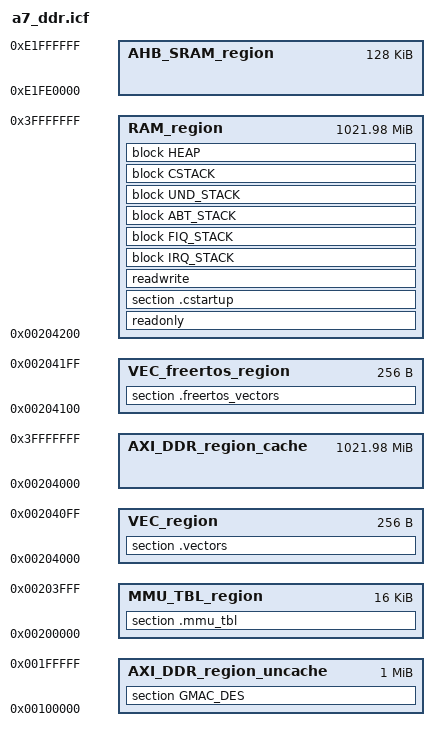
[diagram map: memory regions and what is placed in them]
/*###ICF### Section handled by ICF editor, don't touch! ****/
/*-Editor annotation file-*/
/* IcfEditorFile="$TOOLKIT_DIR$\config\ide\IcfEditor\a_v1_0.xml" */
/*-Memory Regions-*/
define symbol __ICFEDIT_region_ROM_start__ = 0x00000;
define symbol __ICFEDIT_region_ROM_end__   = 0x1ffff;

//define symbol __ICFEDIT_region_RAM_start__ = 0x20000;
define symbol __ICFEDIT_region_RAM_start__ = 0x24000;
define symbol __ICFEDIT_region_RAM_end__   = 0x5FFFF;

/* The AHB sram is uncacheable in default in the mmu_table.s */
define symbol __AHB_SRAM_START = 0xE1FE0000;
define symbol __AHB_SRAM_END = 0xE1FFFFFF;

define symbol __AXI_DDR_UNCACHE_START = 0x00100000;
define symbol __AXI_DDR_UNCACHE_END = 0x001FFFFF;

//define symbol __AXI_DDR_CACHE_START = 0x00200000;
define symbol __AXI_DDR_CACHE_START = 0x00204000;
define symbol __AXI_DDR_CACHE_END = 0x3FFFFFFF;
/*-Sizes-*/
define symbol __ICFEDIT_size_vectors__  = 0x100;
define symbol __ICFEDIT_size_freertos_vectors__  = 0x100;
define symbol __ICFEDIT_size_cstack__   = 0x4000;
define symbol __ICFEDIT_size_irqstack__ = 0x8000;
define symbol __ICFEDIT_size_fiqstack__ = 0x100;
define symbol __ICFEDIT_size_abtstack__ = 0x100;
define symbol __ICFEDIT_size_undstack__ = 0x100;

define symbol __ICFEDIT_size_heap__     = 0x600000;
/*-Exports-*/
export symbol __ICFEDIT_region_RAM_start__;
export symbol __ICFEDIT_region_RAM_end__;
export symbol __ICFEDIT_size_vectors__;
export symbol __ICFEDIT_size_cstack__;
export symbol __ICFEDIT_size_irqstack__;
export symbol __ICFEDIT_size_fiqstack__;

export symbol __ICFEDIT_size_heap__;
/**** End of ICF editor section. ###ICF###*/

define memory mem with size = 4G;
define region VEC_region = mem:[from __AXI_DDR_CACHE_START size __ICFEDIT_size_vectors__];
define region VEC_freertos_region = mem:[from __AXI_DDR_CACHE_START +__ICFEDIT_size_vectors__ size __ICFEDIT_size_freertos_vectors__];
define region RAM_region = mem:[from __AXI_DDR_CACHE_START+__ICFEDIT_size_vectors__+__ICFEDIT_size_freertos_vectors__ to __AXI_DDR_CACHE_END];
define region AHB_SRAM_region = mem:[from __AHB_SRAM_START to __AHB_SRAM_END];
define region AXI_DDR_region_uncache = mem:[from __AXI_DDR_UNCACHE_START to __AXI_DDR_UNCACHE_END];
define region AXI_DDR_region_cache = mem:[from __AXI_DDR_CACHE_START to __AXI_DDR_CACHE_END];

define block CSTACK    with alignment = 8, size = __ICFEDIT_size_cstack__   { };
define block IRQ_STACK with alignment = 8, size = __ICFEDIT_size_irqstack__ { };
define block FIQ_STACK with alignment = 8, size = __ICFEDIT_size_fiqstack__ { };
define block ABT_STACK with alignment = 8, size = __ICFEDIT_size_abtstack__ { };
define block UND_STACK with alignment = 8, size = __ICFEDIT_size_undstack__ { };
define block HEAP      with alignment = 32, size = __ICFEDIT_size_heap__     { };

initialize by copy with packing=none { readwrite };
do not initialize  { readonly section .noinit };

//define region MMU_TBL_region = mem: [from 0x20000 to 0x23FFF];
define region MMU_TBL_region = mem: [from 0x200000 to 0x203fff];
place in MMU_TBL_region { section .mmu_tbl };
place in VEC_freertos_region { section .freertos_vectors };
place in VEC_region { section .vectors };
place in RAM_region { readonly };
place in RAM_region { section .cstartup };

place in RAM_region { readwrite, block IRQ_STACK, block FIQ_STACK, block ABT_STACK, block UND_STACK, block CSTACK };
//place in AHB_SRAM_region {section GMAC_DES};
place in AXI_DDR_region_uncache {section GMAC_DES};
place in RAM_region {block HEAP};

//place in RAM_region { readwrite, block IRQ_STACK, block FIQ_STACK, block ABT_STACK, block UND_STACK, block CSTACK, block HEAP };

//place in AXI_DDR_region {readwrite, block IRQ_STACK, block FIQ_STACK, block ABT_STACK, block UND_STACK, block CSTACK, block HEAP };

/*  all DDR */
//place in AXI_DDR_region_cache { section .mmu_tbl };
//place in AXI_DDR_region_cache {section .vectors, readonly, section .cstartup, readwrite, block IRQ_STACK, block FIQ_STACK, block ABT_STACK, block UND_STACK, block CSTACK, block HEAP };

